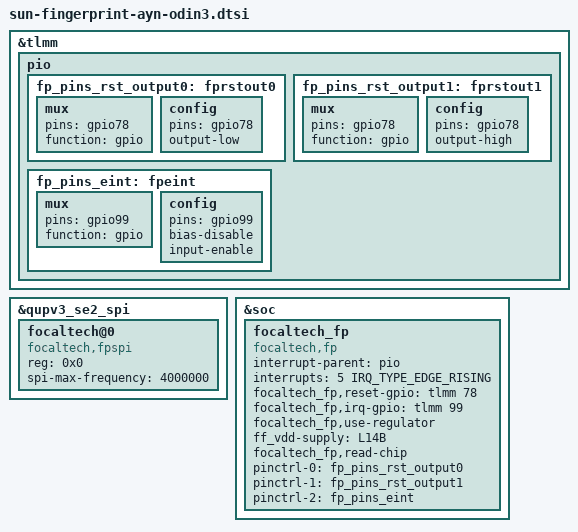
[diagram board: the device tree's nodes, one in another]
#include <dt-bindings/gpio/gpio.h>
#include <dt-bindings/interrupt-controller/irq.h>

&tlmm {
	pio: pio {
		fp_pins_rst_output0: fprstout0 {
			mux {
				pins = "gpio78";
				function = "gpio";
			};

			config {
				pins = "gpio78";
				output-low;
			};
		};

		fp_pins_rst_output1: fprstout1 {
			mux {
				pins = "gpio78";
				function = "gpio";
			};

			config {
				pins = "gpio78";
				output-high;
			};
		};

		fp_pins_eint: fpeint {
			mux {
				pins = "gpio99";
				function = "gpio";
			};

			config {
				pins = "gpio99";
				bias-disable;
				input-enable;
			};
		};
	};
};

&qupv3_se2_spi {
	status = "ok";

	focaltech@0 {
		compatible = "focaltech,fpspi";
		reg = <0x0>;
		spi-max-frequency = <4000000>;
		status = "ok";
	};
};

&soc {
	focaltech_fp: focaltech_fp {
		compatible = "focaltech,fp";
		interrupt-parent = <&pio>;
		interrupts = <5 IRQ_TYPE_EDGE_RISING>;

		focaltech_fp,reset-gpio = <&tlmm 78 0>;
		focaltech_fp,irq-gpio = <&tlmm 99 0>;
		focaltech_fp,use-regulator;

		ff_vdd-supply = <&L14B>;

		focaltech_fp,read-chip;

		pinctrl-names = "ff_pins_reset_low", "ff_pins_reset_high", "ff_pins_irq_as_int", "ff_pins_power_low", "ff_pins_power_high";
		pinctrl-0 = <&fp_pins_rst_output0>;
		pinctrl-1 = <&fp_pins_rst_output1>;
		pinctrl-2 = <&fp_pins_eint>;
	};
};
